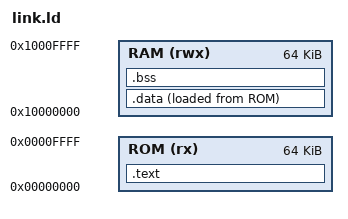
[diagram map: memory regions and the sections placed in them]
/* Memory map of examples/riscv_core.volt:
 *   0x0000_0000  ROM  64 KB  code + read-only data (reset vector at 0)
 *   0x1000_0000  RAM  64 KB  .data, .bss, stack (grows down from the end)
 *   0x2000_0000  I/O         UART, decoded inside the core
 */

OUTPUT_ARCH(riscv)
ENTRY(_start)

MEMORY
{
    ROM (rx)  : ORIGIN = 0x00000000, LENGTH = 64K
    RAM (rwx) : ORIGIN = 0x10000000, LENGTH = 64K
}

SECTIONS
{
    .text : {
        KEEP(*(.text.init))
        *(.text .text.*)
        *(.rodata .rodata.* .srodata .srodata.*)
        . = ALIGN(4);
    } > ROM

    .data : {
        _data_start = .;
        *(.data .data.* .sdata .sdata.*)
        . = ALIGN(4);
        _data_end = .;
    } > RAM AT > ROM
    _data_load = LOADADDR(.data);

    .bss (NOLOAD) : {
        _bss_start = .;
        *(.bss .bss.* .sbss .sbss.* COMMON)
        . = ALIGN(4);
        _bss_end = .;
    } > RAM

    _stack_top = ORIGIN(RAM) + LENGTH(RAM);

    /DISCARD/ : { *(.comment) *(.note*) *(.eh_frame) *(.riscv.attributes) }
}
